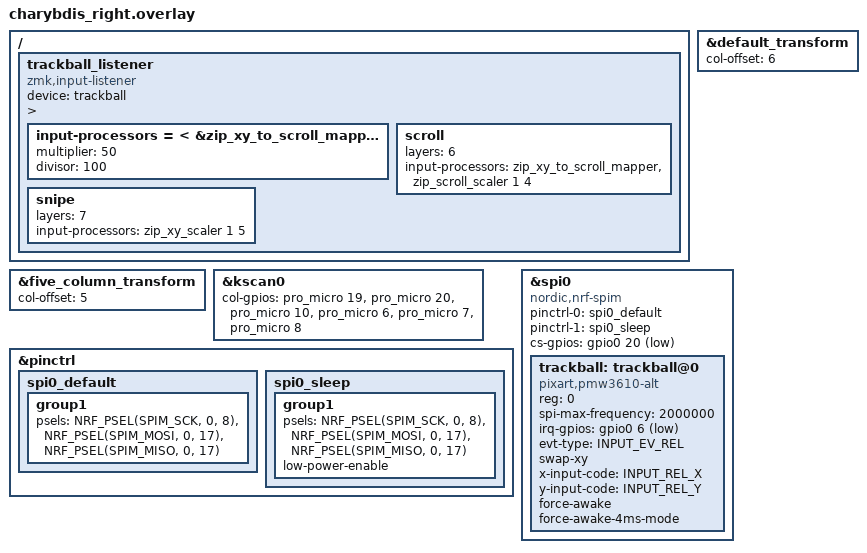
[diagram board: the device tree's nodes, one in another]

/*
 * Copyright (c) 2020 ZMK Contributors
 *
 * SPDX-License-Identifier: MIT
 */
 
#include "charybdis.dtsi"
#include <input/processors.dtsi>

&default_transform {
	col-offset = <6>;
};

&five_column_transform {
	col-offset = <5>;
};

&kscan0 {
	col-gpios
		= <&pro_micro 19 (GPIO_ACTIVE_HIGH | GPIO_PULL_DOWN)>
		, <&pro_micro 20 (GPIO_ACTIVE_HIGH | GPIO_PULL_DOWN)>
		, <&pro_micro 10 (GPIO_ACTIVE_HIGH | GPIO_PULL_DOWN)>
		, <&pro_micro 6 (GPIO_ACTIVE_HIGH | GPIO_PULL_DOWN)>
		, <&pro_micro 7 (GPIO_ACTIVE_HIGH | GPIO_PULL_DOWN)>
		, <&pro_micro 8 (GPIO_ACTIVE_HIGH | GPIO_PULL_DOWN)>
		;
};

&pinctrl {
    spi0_default: spi0_default {
        group1 {
            psels = <NRF_PSEL(SPIM_SCK, 0, 8)>,
                <NRF_PSEL(SPIM_MOSI, 0, 17)>,
                <NRF_PSEL(SPIM_MISO, 0, 17)>;
        };
    };

    spi0_sleep: spi0_sleep {
        group1 {
            psels = <NRF_PSEL(SPIM_SCK, 0, 8)>,
                <NRF_PSEL(SPIM_MOSI, 0, 17)>,
                <NRF_PSEL(SPIM_MISO, 0, 17)>;
            low-power-enable;
        };
    };
};

&spi0 {
    status = "okay";
    compatible = "nordic,nrf-spim";
    pinctrl-0 = <&spi0_default>;
    pinctrl-1 = <&spi0_sleep>;
    pinctrl-names = "default", "sleep";
    cs-gpios = <&gpio0 20 GPIO_ACTIVE_LOW>;

    trackball: trackball@0 {
        status = "okay";
		compatible = "pixart,pmw3610-alt";
        reg = <0>;
        spi-max-frequency = <2000000>;
        irq-gpios = <&gpio0 6 (GPIO_ACTIVE_LOW | GPIO_PULL_UP)>;
		evt-type = <INPUT_EV_REL>;
		swap-xy;
		x-input-code = <INPUT_REL_X>;
        y-input-code = <INPUT_REL_Y>;
		force-awake;
		force-awake-4ms-mode;
        //scroll-layers = <6>;
        //,snipe-layers = <7>;
    };
};

/ {
  trackball_listener {
    compatible = "zmk,input-listener";
    device = <&trackball>;
input-processors = <
        /* 先映射 XY → scroll（如果还没做） */
        &zip_xy_to_scroll_mapper

        /* 再调节幅度：乘以 2.0 → 滚动幅度变大一倍；乘以 0.5 → 变小一半 */
        &zip_scroll_scaler {
            multiplier = <50>;   // 分子，200 = 2.0 倍
            divisor    = <100>;   // 分母，通常保持 100
        }

        /* 可选：再加个反转（如果方向相反） */
        /* &zip_scroll_transform { flags = <INPUT_TRANSFORM_SCROLL_Y_INVERT>; } */
    >;
	scroll {
		    layers = <6>;
		    input-processors = <
		        &zip_xy_to_scroll_mapper  // 只留这个，移除 scaler 先
				&zip_scroll_scaler 1 4
		    >;
	};
	snipe {
        	layers = <7>;        // 你的精密层号，比如 4
        	input-processors = <
            	&zip_xy_scaler 1 5   // 1/5 速 = 超级慢精密（推荐起步值）
        	>;
    };
  };
};





